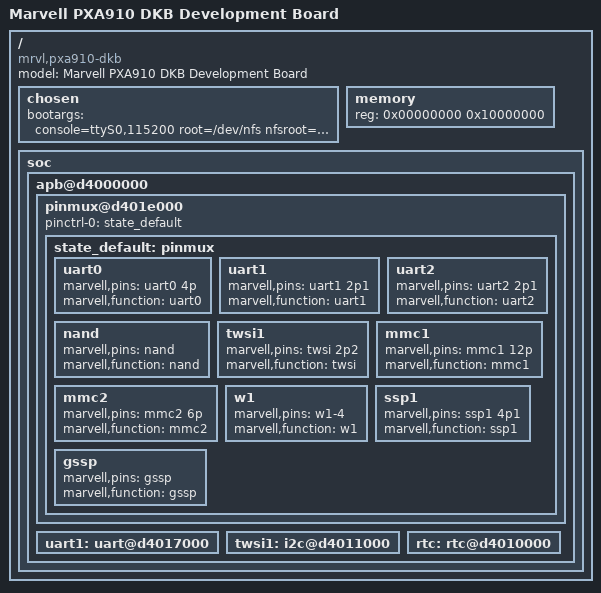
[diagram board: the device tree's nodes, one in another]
/*
 *  Copyright (C) 2012 Marvell Technology Group Ltd.
 *  Author: Haojian Zhuang <haojian.zhuang@marvell.com>
 *
 *  This program is free software; you can redistribute it and/or modify
 *  it under the terms of the GNU General Public License version 2 as
 *  publishhed by the Free Software Foundation.
 */

/dts-v1/;
/include/ "pxa910.dtsi"

/ {
	model = "Marvell PXA910 DKB Development Board";
	compatible = "mrvl,pxa910-dkb", "mrvl,pxa910";

	chosen {
		bootargs = "console=ttyS0,115200 root=/dev/nfs nfsroot=192.168.1.100:/nfsroot/ ip=192.168.1.101:192.168.1.100::255.255.255.0::eth0:on";
	};

	memory {
		reg = <0x00000000 0x10000000>;
	};

	soc {
		apb@d4000000 {
			pinmux@d401e000 {
				pinctrl-names = "default";
				pinctrl-0 = <&state_default>;

				state_default: pinmux {
					uart0 { /* BT UART */
						marvell,pins = "uart0 4p";
						marvell,function = "uart0";
					};
					uart1 {	/* Serial UART */
						marvell,pins = "uart1 2p1";
						marvell,function = "uart1";
					};
					uart2 { /* GPS UART */
						marvell,pins = "uart2 2p1";
						marvell,function = "uart2";
					};
					nand {
						marvell,pins = "nand";
						marvell,function = "nand";
					};
					twsi1 {
						marvell,pins = "twsi 2p2";
						marvell,function = "twsi";
					};
					mmc1 {
						marvell,pins = "mmc1 12p";
						marvell,function = "mmc1";
					};
					mmc2 {
						marvell,pins = "mmc2 6p";
						marvell,function = "mmc2";
					};
					w1 {
						marvell,pins = "w1-4";
						marvell,function = "w1";
					};
					ssp1 {
						marvell,pins = "ssp1 4p1";
						marvell,function = "ssp1";
					};
					gssp {
						marvell,pins = "gssp";
						marvell,function = "gssp";
					};
				};
			};
			uart1: uart@d4017000 {
				status = "okay";
			};
			twsi1: i2c@d4011000 {
				status = "okay";
			};
			rtc: rtc@d4010000 {
				status = "okay";
			};
		};
	};
};
